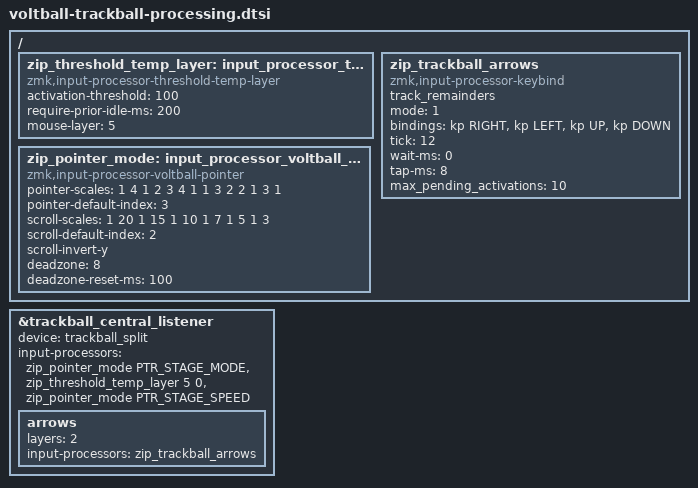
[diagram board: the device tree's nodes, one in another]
#include <input/processors.dtsi>
#include <input/processors/zmk-input-processor-keybind.dtsi>
#include <dt-bindings/zmk/keys.h>
#include <dt-bindings/zmk/input_transform.h>
#include <dt-bindings/voltball/pointer_mode.h>
/ {
    
    zip_threshold_temp_layer: input_processor_threshold_temp_layer {
        compatible = "zmk,input-processor-threshold-temp-layer";
        #input-processor-cells = <2>;
        
        activation-threshold = <100>;
        
        // Ignore residual motion immediately after typing.
        require-prior-idle-ms = <200>;

        // MOUSE layer index; must match the listener cell below.
        mouse-layer = <5>;
    };

    
    // &ptr speed steps (mul div) and scroll mode; replaces the SCROLL layer.
    zip_pointer_mode: input_processor_voltball_pointer {
        compatible = "zmk,input-processor-voltball-pointer";
        #input-processor-cells = <1>;
        // x1/4 x1/2 x3/4 x1 x3/2 x2 x3
        pointer-scales = <1 4  1 2  3 4  1 1  3 2  2 1  3 1>;
        pointer-default-index = <3>;
        // x1/20 x1/15 x1/10 x1/7 x1/5 x1/3; x1/10 matches the former SCROLL layer.
        scroll-scales = <1 20  1 15  1 10  1 7  1 5  1 3>;
        scroll-default-index = <2>;
        scroll-invert-y;
        // Ignore light touches: after a 100ms rest, motion starts only past 8 counts.
        deadzone = <8>;
        deadzone-reset-ms = <100>;
    };

    zip_trackball_arrows: zip_trackball_arrows {
        compatible = "zmk,input-processor-keybind";
        #input-processor-cells = <0>;
        track_remainders;
        mode = <1>;
        bindings = <&kp RIGHT>,
                   <&kp LEFT>,
                   <&kp UP>,
                   <&kp DOWN>;
        tick = <12>;
        wait-ms = <0>;
        tap-ms = <8>;
        max_pending_activations = <10>;
    };
};

&trackball_central_listener {
    status = "okay";
    device = <&trackball_split>;

    
    // Scroll mode converts motion first, so it never latches auto mouse.
    // Auto mouse is latched until a non-modifier key that is &trans on MOUSE; no timeout.
    // Speed scales pointer motion after the auto mouse threshold sees raw counts.
    input-processors = <&zip_pointer_mode PTR_STAGE_MODE>,
                       <&zip_threshold_temp_layer 5 0>,
                       <&zip_pointer_mode PTR_STAGE_SPEED>;

    
    arrows {
        layers = <2>;
        input-processors = <&zip_trackball_arrows>;
    };
};
